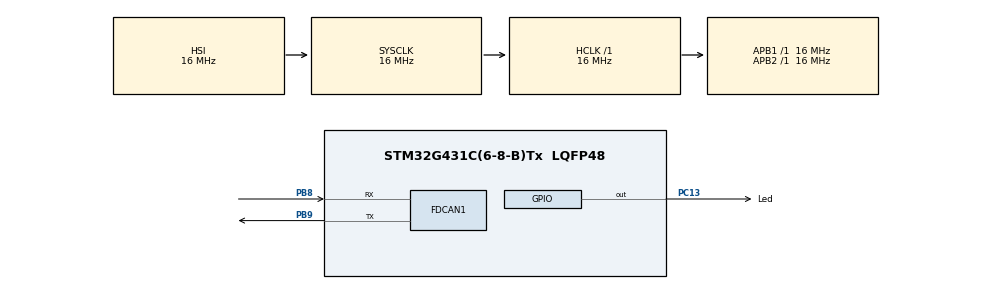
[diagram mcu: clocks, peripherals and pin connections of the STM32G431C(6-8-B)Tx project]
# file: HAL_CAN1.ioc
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FDCAN1.AutoRetransmission=DISABLE
FDCAN1.CalculateBaudRateNominal=200000
FDCAN1.CalculateTimeBitNominal=5000
FDCAN1.CalculateTimeQuantumNominal=1000.0
FDCAN1.ProtocolException=DISABLE
Mcu.Family=STM32G4
Mcu.Name=STM32G431C(6-8-B)Tx
Mcu.Package=LQFP48
NVIC.PriorityGroup=NVIC_PRIORITYGROUP_4
PB8-BOOT0.Mode=FDCAN_Activate
PB8-BOOT0.Signal=FDCAN1_RX
PB9.Mode=FDCAN_Activate
PB9.Signal=FDCAN1_TX
PC13.GPIO_Label=Led
PC13.Signal=GPIO_Output
ProjectManager.HeapSize=0x200
ProjectManager.StackSize=0x400
ProjectManager.TargetToolchain=STM32CubeIDE
RCC.AHBFreq_Value=16000000
RCC.APB1Freq_Value=16000000
RCC.APB1TimFreq_Value=16000000
RCC.APB2Freq_Value=16000000
RCC.APB2TimFreq_Value=16000000
RCC.CortexFreq_Value=16000000
RCC.EXTERNAL_CLOCK_VALUE=12288000
RCC.HCLKFreq_Value=16000000
RCC.HSE_VALUE=8000000
RCC.HSI48_VALUE=48000000
RCC.HSI_VALUE=16000000
RCC.LSE_VALUE=32768
RCC.SYSCLKFreq_VALUE=16000000
RCC.USBFreq_Value=64000000
RCC.VCOOutputFreq_Value=128000000
board=custom

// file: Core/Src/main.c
/* USER CODE BEGIN Header */
/**
  ******************************************************************************
  * @file           : main.c
  * @brief          : Main program body
  ******************************************************************************
  * @attention
  *
  * Copyright (c) 2024 STMicroelectronics.
  * All rights reserved.
  *
  * This software is licensed under terms that can be found in the LICENSE file
  * in the root directory of this software component.
  * If no LICENSE file comes with this software, it is provided AS-IS.
  *
  ******************************************************************************
  */
/* USER CODE END Header */
#include "main.h"

FDCAN_HandleTypeDef hfdcan1;

void SystemClock_Config(void);
static void MX_GPIO_Init(void);
static void MX_FDCAN1_Init(void);

int main(void)
{

  /* MCU Configuration--------------------------------------------------------*/

  /* Reset of all peripherals, Initializes the Flash interface and the Systick. */
  HAL_Init();

  /* Configure the system clock */
  SystemClock_Config();

  /* Initialize all configured peripherals */
  MX_GPIO_Init();
  MX_FDCAN1_Init();
  /* USER CODE BEGIN 2 */
  	const uint8_t data[5] = "Hello";
	FDCAN_TxHeaderTypeDef Hframe;
	Hframe.Identifier = 0x09;
	Hframe.IdType = FDCAN_STANDARD_ID;
	Hframe.TxFrameType = FDCAN_DATA_FRAME;
	Hframe.DataLength = 5;
	Hframe.ErrorStateIndicator = FDCAN_ESI_PASSIVE;
	Hframe.BitRateSwitch = FDCAN_BRS_OFF;
	Hframe.FDFormat = FDCAN_CLASSIC_CAN;
	Hframe.TxEventFifoControl = FDCAN_NO_TX_EVENTS;
	Hframe.MessageMarker = 0x11;

	HAL_FDCAN_Start(&hfdcan1);
  /* USER CODE END 2 */

  /* Infinite loop */
  /* USER CODE BEGIN WHILE */
  while (1)
  {

	  HAL_FDCAN_AddMessageToTxFifoQ(&hfdcan1, &Hframe, data);

	  HAL_GPIO_TogglePin(Led_GPIO_Port, Led_Pin);
	  HAL_Delay(500);
    /* USER CODE END WHILE */

  }
}

void SystemClock_Config(void)
{
  RCC_OscInitTypeDef RCC_OscInitStruct = {0};
  RCC_ClkInitTypeDef RCC_ClkInitStruct = {0};

  /** Configure the main internal regulator output voltage
  */
  HAL_PWREx_ControlVoltageScaling(PWR_REGULATOR_VOLTAGE_SCALE1);

  /** Initializes the RCC Oscillators according to the specified parameters
  * in the RCC_OscInitTypeDef structure.
  */
  RCC_OscInitStruct.OscillatorType = RCC_OSCILLATORTYPE_HSI;
  RCC_OscInitStruct.HSIState = RCC_HSI_ON;
  RCC_OscInitStruct.HSICalibrationValue = RCC_HSICALIBRATION_DEFAULT;
  RCC_OscInitStruct.PLL.PLLState = RCC_PLL_NONE;
  if (HAL_RCC_OscConfig(&RCC_OscInitStruct) != HAL_OK)
  {
    Error_Handler();
  }

  /** Initializes the CPU, AHB and APB buses clocks
  */
  RCC_ClkInitStruct.ClockType = RCC_CLOCKTYPE_HCLK|RCC_CLOCKTYPE_SYSCLK
                              |RCC_CLOCKTYPE_PCLK1|RCC_CLOCKTYPE_PCLK2;
  RCC_ClkInitStruct.SYSCLKSource = RCC_SYSCLKSOURCE_HSI;
  RCC_ClkInitStruct.AHBCLKDivider = RCC_SYSCLK_DIV1;
  RCC_ClkInitStruct.APB1CLKDivider = RCC_HCLK_DIV1;
  RCC_ClkInitStruct.APB2CLKDivider = RCC_HCLK_DIV1;

  if (HAL_RCC_ClockConfig(&RCC_ClkInitStruct, FLASH_LATENCY_0) != HAL_OK)
  {
    Error_Handler();
  }
}

static void MX_FDCAN1_Init(void)
{

  hfdcan1.Instance = FDCAN1;
  hfdcan1.Init.ClockDivider = FDCAN_CLOCK_DIV1;
  hfdcan1.Init.FrameFormat = FDCAN_FRAME_CLASSIC;
  hfdcan1.Init.Mode = FDCAN_MODE_NORMAL;
  hfdcan1.Init.AutoRetransmission = DISABLE;
  hfdcan1.Init.TransmitPause = DISABLE;
  hfdcan1.Init.ProtocolException = DISABLE;
  hfdcan1.Init.NominalPrescaler = 16;
  hfdcan1.Init.NominalSyncJumpWidth = 1;
  hfdcan1.Init.NominalTimeSeg1 = 2;
  hfdcan1.Init.NominalTimeSeg2 = 2;
  hfdcan1.Init.DataPrescaler = 1;
  hfdcan1.Init.DataSyncJumpWidth = 1;
  hfdcan1.Init.DataTimeSeg1 = 1;
  hfdcan1.Init.DataTimeSeg2 = 1;
  hfdcan1.Init.StdFiltersNbr = 0;
  hfdcan1.Init.ExtFiltersNbr = 0;
  hfdcan1.Init.TxFifoQueueMode = FDCAN_TX_FIFO_OPERATION;
  if (HAL_FDCAN_Init(&hfdcan1) != HAL_OK)
  {
    Error_Handler();
  }

}

static void MX_GPIO_Init(void)
{
  GPIO_InitTypeDef GPIO_InitStruct = {0};

  /* GPIO Ports Clock Enable */
  __HAL_RCC_GPIOC_CLK_ENABLE();
  __HAL_RCC_GPIOB_CLK_ENABLE();

  /*Configure GPIO pin Output Level */
  HAL_GPIO_WritePin(Led_GPIO_Port, Led_Pin, GPIO_PIN_RESET);

  /*Configure GPIO pin : Led_Pin */
  GPIO_InitStruct.Pin = Led_Pin;
  GPIO_InitStruct.Mode = GPIO_MODE_OUTPUT_PP;
  GPIO_InitStruct.Pull = GPIO_NOPULL;
  GPIO_InitStruct.Speed = GPIO_SPEED_FREQ_LOW;
  HAL_GPIO_Init(Led_GPIO_Port, &GPIO_InitStruct);

}

void Error_Handler(void)
{
  __disable_irq();
  while (1)
  {
  }
}
